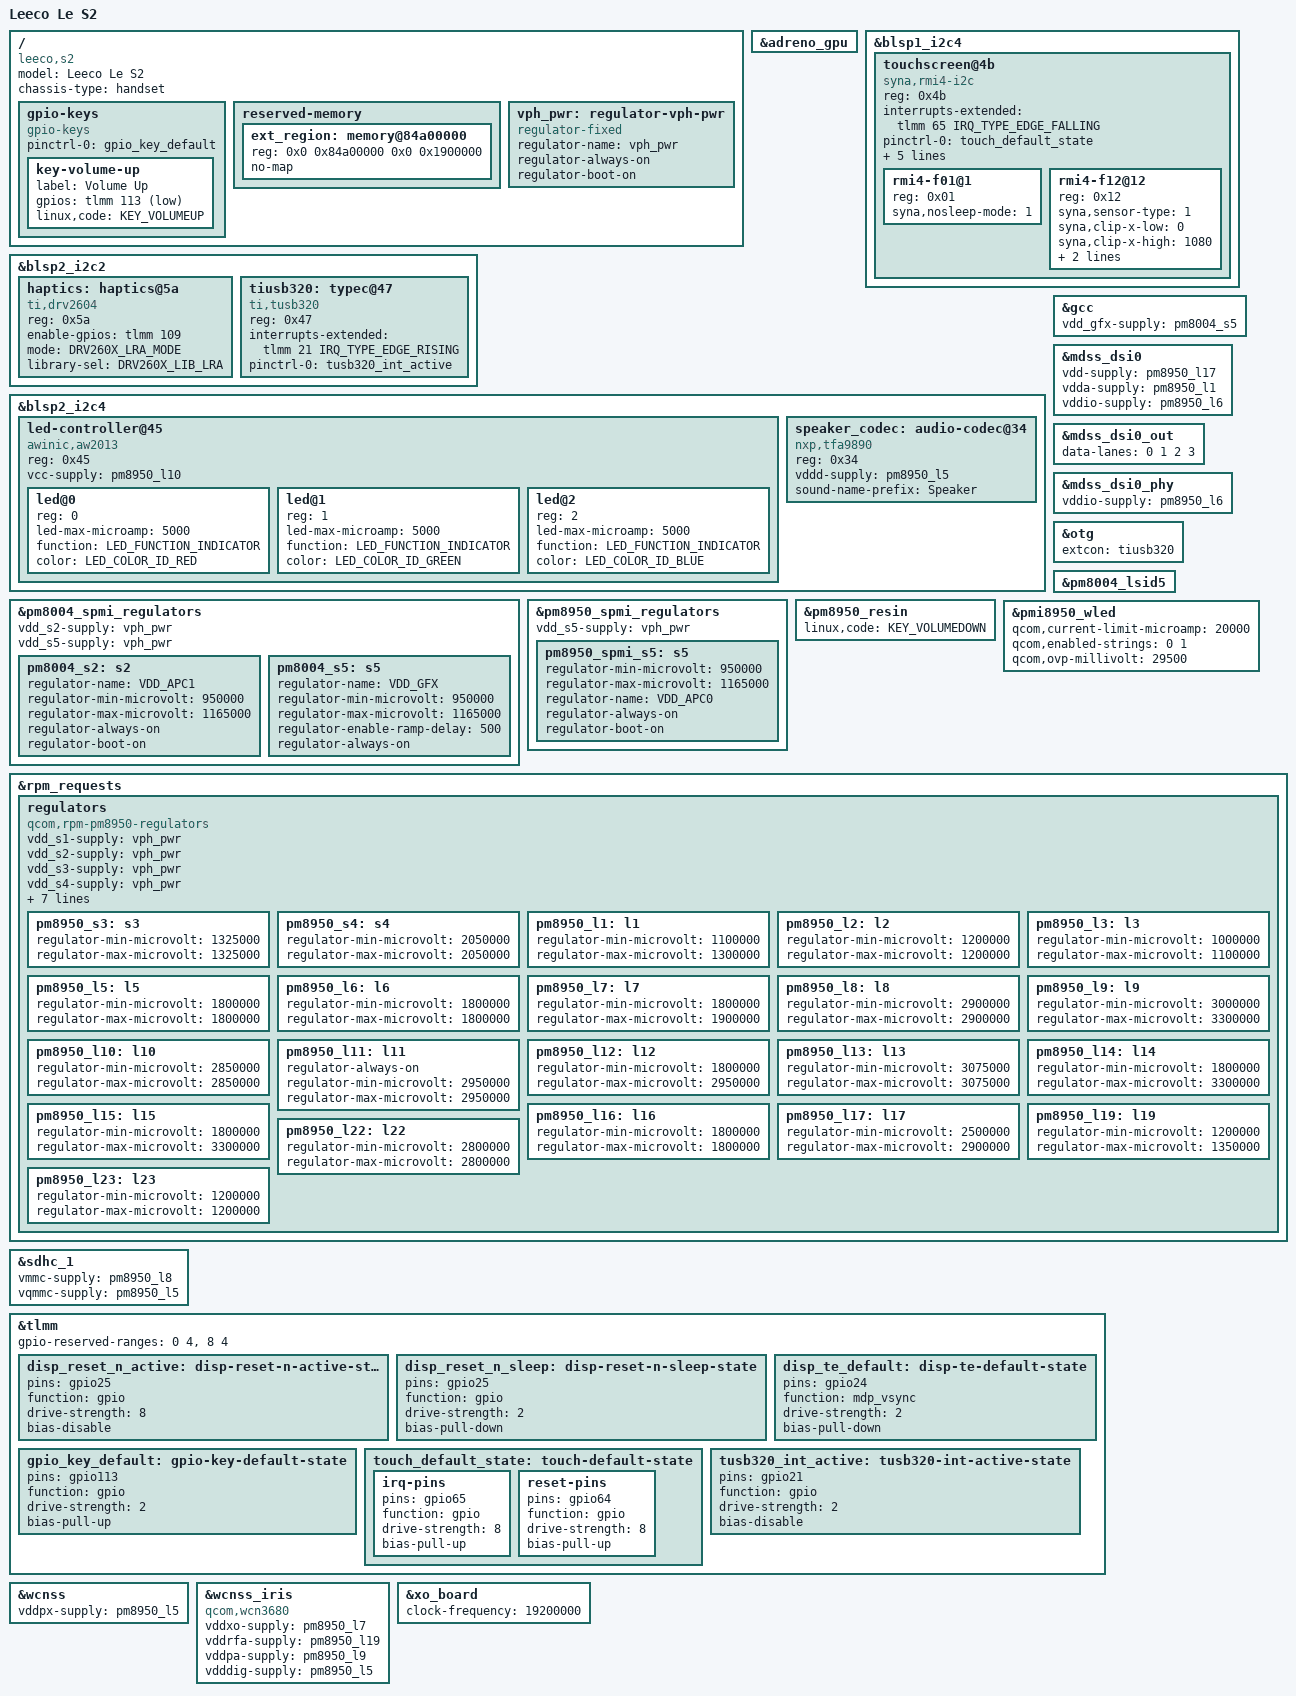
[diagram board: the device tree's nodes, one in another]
// SPDX-License-Identifier: (GPL-2.0+ OR BSD-3-Clause)
/*
 * Copyright (c) 2026 Adam Skladowski <a39skl@gmail.com>
 */

/dts-v1/;

#include "msm8976.dtsi"
#include "pm8950.dtsi"
#include "pm8004.dtsi"
#include "pmi8950.dtsi"
#include <dt-bindings/interrupt-controller/irq.h>
#include <dt-bindings/gpio/gpio.h>
#include <dt-bindings/input/gpio-keys.h>
#include <dt-bindings/input/input.h>
#include <dt-bindings/input/linux-event-codes.h>
#include <dt-bindings/pinctrl/qcom,pmic-gpio.h>
#include <dt-bindings/leds/common.h>
#include <dt-bindings/input/ti-drv260x.h>

/ {
	model = "Leeco Le S2";
	compatible = "leeco,s2", "qcom,msm8976";
	chassis-type = "handset";

	gpio-keys {
		compatible = "gpio-keys";

		pinctrl-0 = <&gpio_key_default>;
		pinctrl-names = "default";

		key-volume-up {
			label = "Volume Up";
			gpios = <&tlmm 113 GPIO_ACTIVE_LOW>;
			linux,code = <KEY_VOLUMEUP>;
		};
	};

	reserved-memory {
		/delete-node/ ext-region@85b00000;

		 ext_region: memory@84a00000 {
			reg = <0x0 0x84a00000 0x0 0x1900000>;
			no-map;
		};
	};

	vph_pwr: regulator-vph-pwr {
		compatible = "regulator-fixed";
		regulator-name = "vph_pwr";
		regulator-always-on;
		regulator-boot-on;
	};
};

&adreno_gpu {
	status = "okay";
};

&blsp1_i2c4 {
	status = "okay";

	touchscreen@4b {
		compatible = "syna,rmi4-i2c";
		reg = <0x4b>;
		interrupts-extended = <&tlmm 65 IRQ_TYPE_EDGE_FALLING>;

		pinctrl-0 = <&touch_default_state>;
		pinctrl-names = "default";

		reset-gpios = <&tlmm 64 GPIO_ACTIVE_HIGH>;

		vdd-supply = <&pm8950_l17>;
		vio-supply = <&pm8950_l6>;

		syna,reset-delay-ms = <100>;
		syna,startup-delay-ms = <500>;

		#address-cells = <1>;
		#size-cells = <0>;

		rmi4-f01@1 {
			reg = <0x01>;
			syna,nosleep-mode = <1>;
		};

		rmi4-f12@12 {
			reg = <0x12>;
			syna,sensor-type = <1>;
			syna,clip-x-low = <0>;
			syna,clip-x-high = <1080>;
			syna,clip-y-low = <0>;
			syna,clip-y-high = <1920>;
		};
	};
};

&blsp2_i2c2 {
	status = "okay";

	haptics: haptics@5a {
		compatible = "ti,drv2604";
		reg = <0x5a>;
		enable-gpios = <&tlmm 109 GPIO_ACTIVE_HIGH>;
		mode = <DRV260X_LRA_MODE>;
		library-sel = <DRV260X_LIB_LRA>;
	};

	tiusb320: typec@47 {
		compatible = "ti,tusb320";
		reg = <0x47>;
		interrupts-extended = <&tlmm 21 IRQ_TYPE_EDGE_RISING>;

		pinctrl-0 = <&tusb320_int_active>;
		pinctrl-names = "default";
	};
};

&blsp2_i2c4 {
	status = "okay";

	led-controller@45 {
		compatible = "awinic,aw2013";
		reg = <0x45>;
		vcc-supply = <&pm8950_l10>;

		#address-cells = <1>;
		#size-cells = <0>;

		led@0 {
			reg = <0>;
			led-max-microamp = <5000>;
			function = LED_FUNCTION_INDICATOR;
			color = <LED_COLOR_ID_RED>;
		};

		led@1 {
			reg = <1>;
			led-max-microamp = <5000>;
			function = LED_FUNCTION_INDICATOR;
			color = <LED_COLOR_ID_GREEN>;
		};

		led@2 {
			reg = <2>;
			led-max-microamp = <5000>;
			function = LED_FUNCTION_INDICATOR;
			color = <LED_COLOR_ID_BLUE>;
		};
	};

	speaker_codec: audio-codec@34 {
		compatible = "nxp,tfa9890";
		reg = <0x34>;
		vddd-supply = <&pm8950_l5>;
		sound-name-prefix = "Speaker";
		#sound-dai-cells = <0>;
	};
};

&gcc {
	vdd_gfx-supply = <&pm8004_s5>;
};

&mdss_dsi0 {
	vdd-supply = <&pm8950_l17>;
	vdda-supply = <&pm8950_l1>;
	vddio-supply = <&pm8950_l6>;
};

&mdss_dsi0_out {
	data-lanes = <0 1 2 3>;
};

&mdss_dsi0_phy {
	vddio-supply = <&pm8950_l6>;
};

&otg {
	extcon = <&tiusb320>;
};

&pm8004_lsid5 {
	status = "okay";
};

&pm8004_spmi_regulators {
	vdd_s2-supply = <&vph_pwr>;
	vdd_s5-supply = <&vph_pwr>;

	status = "okay";

	/* Cluster 1 supply */
	pm8004_s2: s2 {
		regulator-name = "VDD_APC1";
		regulator-min-microvolt = <950000>;
		regulator-max-microvolt = <1165000>;
		regulator-always-on;
		regulator-boot-on;
	};

	pm8004_s5: s5 {
		regulator-name = "VDD_GFX";
		regulator-min-microvolt = <950000>;
		regulator-max-microvolt = <1165000>;
		regulator-enable-ramp-delay = <500>;
		regulator-always-on;
	};
};

&pm8950_spmi_regulators {
	vdd_s5-supply = <&vph_pwr>;

	/* Cluster 0 supply */
	pm8950_spmi_s5: s5 {
		regulator-min-microvolt = <950000>;
		regulator-max-microvolt = <1165000>;
		regulator-name = "VDD_APC0";
		regulator-always-on;
		regulator-boot-on;
	};
};

&pm8950_resin {
	linux,code = <KEY_VOLUMEDOWN>;

	status = "okay";
};

&pmi8950_wled {
	qcom,current-limit-microamp = <20000>;
	qcom,enabled-strings = <0 1>;
	qcom,ovp-millivolt = <29500>;
};

&rpm_requests {
	regulators {
		compatible = "qcom,rpm-pm8950-regulators";

		vdd_s1-supply = <&vph_pwr>;
		vdd_s2-supply = <&vph_pwr>;
		vdd_s3-supply = <&vph_pwr>;
		vdd_s4-supply = <&vph_pwr>;
		vdd_s6-supply = <&vph_pwr>;
		vdd_l1_l19-supply = <&pm8950_s3>;
		vdd_l2_l23-supply = <&pm8950_s3>;
		vdd_l3-supply = <&pm8950_s3>;
		vdd_l5_l6_l7_l16-supply = <&pm8950_s4>;
		vdd_l8_l11_l12_l17_l22-supply = <&vph_pwr>;
		vdd_l9_l10_l13_l14_l15_l18-supply = <&vph_pwr>;

		pm8950_s3: s3 {
			regulator-min-microvolt = <1325000>;
			regulator-max-microvolt = <1325000>;
		};

		pm8950_s4: s4 {
			regulator-min-microvolt = <2050000>;
			regulator-max-microvolt = <2050000>;
		};

		pm8950_l1: l1 {
			regulator-min-microvolt = <1100000>;
			regulator-max-microvolt = <1300000>;
		};

		pm8950_l2: l2 {
			regulator-min-microvolt = <1200000>;
			regulator-max-microvolt = <1200000>;
		};

		pm8950_l3: l3 {
			regulator-min-microvolt = <1000000>;
			regulator-max-microvolt = <1100000>;
		};

		pm8950_l5: l5 {
			regulator-min-microvolt = <1800000>;
			regulator-max-microvolt = <1800000>;
		};

		pm8950_l6: l6 {
			regulator-min-microvolt = <1800000>;
			regulator-max-microvolt = <1800000>;
		};

		pm8950_l7: l7 {
			regulator-min-microvolt = <1800000>;
			regulator-max-microvolt = <1900000>;
		};

		pm8950_l8: l8 {
			regulator-min-microvolt = <2900000>;
			regulator-max-microvolt = <2900000>;
		};

		pm8950_l9: l9 {
			regulator-min-microvolt = <3000000>;
			regulator-max-microvolt = <3300000>;
		};

		pm8950_l10: l10 {
			regulator-min-microvolt = <2850000>;
			regulator-max-microvolt = <2850000>;
		};

		pm8950_l11: l11 {
		/* TUSB320 power supply */
			regulator-always-on;
			regulator-min-microvolt = <2950000>;
			regulator-max-microvolt = <2950000>;
		};

		pm8950_l12: l12 {
			regulator-min-microvolt = <1800000>;
			regulator-max-microvolt = <2950000>;
		};

		pm8950_l13: l13 {
			regulator-min-microvolt = <3075000>;
			regulator-max-microvolt = <3075000>;
		};

		pm8950_l14: l14 {
			regulator-min-microvolt = <1800000>;
			regulator-max-microvolt = <3300000>;
		};

		pm8950_l15: l15 {
			regulator-min-microvolt = <1800000>;
			regulator-max-microvolt = <3300000>;
		};

		pm8950_l16: l16 {
			regulator-min-microvolt = <1800000>;
			regulator-max-microvolt = <1800000>;
		};

		pm8950_l17: l17 {
			regulator-min-microvolt = <2500000>;
			regulator-max-microvolt = <2900000>;
		};

		pm8950_l19: l19 {
			regulator-min-microvolt = <1200000>;
			regulator-max-microvolt = <1350000>;
		};

		pm8950_l22: l22 {
			regulator-min-microvolt = <2800000>;
			regulator-max-microvolt = <2800000>;
		};

		pm8950_l23: l23 {
			regulator-min-microvolt = <1200000>;
			regulator-max-microvolt = <1200000>;
		};
	};
};

&sdhc_1 {
	vmmc-supply = <&pm8950_l8>;
	vqmmc-supply = <&pm8950_l5>;

	status = "okay";
};

&tlmm {
	gpio-reserved-ranges = <0 4>, /* Unknown */
			       <8 4>; /* Fingerprint SPI */

	disp_reset_n_active: disp-reset-n-active-state {
		pins = "gpio25";
		function = "gpio";
		drive-strength = <8>;
		bias-disable;
	};

	disp_reset_n_sleep: disp-reset-n-sleep-state {
		pins = "gpio25";
		function = "gpio";
		drive-strength = <2>;
		bias-pull-down;
	};

	disp_te_default: disp-te-default-state {
		pins = "gpio24";
		function = "mdp_vsync";
		drive-strength = <2>;
		bias-pull-down;
	};

	gpio_key_default: gpio-key-default-state {
		pins = "gpio113";
		function = "gpio";
		drive-strength = <2>;
		bias-pull-up;
	};

	touch_default_state: touch-default-state {
		irq-pins {
			pins = "gpio65";
			function = "gpio";
			drive-strength = <8>;
			bias-pull-up;
		};

		reset-pins {
			pins = "gpio64";
			function = "gpio";
			drive-strength = <8>;
			bias-pull-up;
		};
	};

	tusb320_int_active: tusb320-int-active-state {
		pins = "gpio21";
		function = "gpio";
		drive-strength = <2>;
		bias-disable;
	};
};

&wcnss {
	vddpx-supply = <&pm8950_l5>;

	status = "okay";
};

&wcnss_iris {
	compatible = "qcom,wcn3680";

	vddxo-supply = <&pm8950_l7>;
	vddrfa-supply = <&pm8950_l19>;
	vddpa-supply = <&pm8950_l9>;
	vdddig-supply = <&pm8950_l5>;
};

&xo_board {
	clock-frequency = <19200000>;
};

